AUTOSAR XML (schema 4-2-2)
package /Components
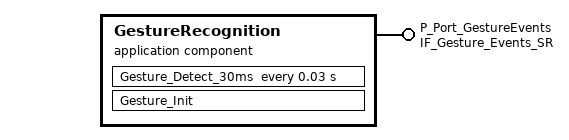
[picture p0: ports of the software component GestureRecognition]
  application sw component type GestureRecognition
    provide port P_Port_GestureEvents: provided-interface=IF_Gesture_Events_SR
    behavior GestureRecognition_InternalBehavior
      init event Gesture_Init_Event: start-on-event=Gesture_Init
      timing event Gesture_Tick: start-on-event=Gesture_Detect_30ms, period=0.03
      runnable Gesture_Init
        parameter access PA_Read_Gesture_Params: accessed-parameter=P_Port_GestureEvents.Gesture_Confidence
      runnable Gesture_Detect_30ms: minimum-start-interval=0.03
        data-send-points:
          access VA_Send_Gesture_Type: accessed-variable=P_Port_GestureEvents.Gesture_Type
          access VA_Send_Gesture_Confidence: accessed-variable=P_Port_GestureEvents.Gesture_Confidence
          access VA_Send_Timestamp: accessed-variable=P_Port_GestureEvents.Timestamp
